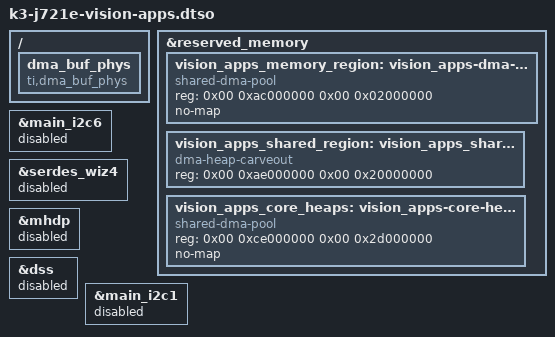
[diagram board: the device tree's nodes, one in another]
// SPDX-License-Identifier: GPL-2.0
/*
 * Vision-apps: device-tree overlay
 *
 * Copyright (C) 2019 Texas Instruments Incorporated - http://www.ti.com/
 */

#include <dt-bindings/soc/ti,sci_pm_domain.h>

/dts-v1/;
/plugin/;

/ {
	fragment@101 {
		target-path = "/";

		__overlay__ {

			dma_buf_phys {
				compatible = "ti,dma_buf_phys";
			};
		};
	};
};

&reserved_memory {
	#address-cells = <2>;
	#size-cells = <2>;

	vision_apps_memory_region: vision_apps-dma-memory@ac000000 {
		compatible = "shared-dma-pool";
		reg = <0x00 0xac000000 0x00 0x02000000>;
		no-map;
	};
	vision_apps_shared_region: vision_apps_shared-memories {
		compatible = "dma-heap-carveout";
		reg = <0x00 0xae000000 0x00 0x20000000>;
	};
	vision_apps_core_heaps: vision_apps-core-heap-memory@ce000000 {
		compatible = "shared-dma-pool";
		reg = <0x00 0xce000000 0x00 0x2d000000>;
		no-map;
	};
};

&main_i2c6 {
	status = "disabled";
};

&serdes_wiz4 {
	status = "disabled";
};

&mhdp {
	status = "disabled";
};

&dss {
	status = "disabled";
};

&main_i2c1 {
	status = "disabled";
};
